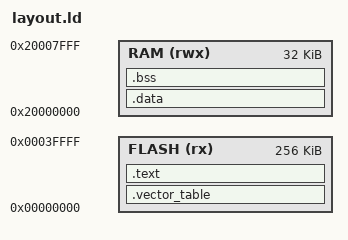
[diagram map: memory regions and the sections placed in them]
MEMORY
{
    FLASH (rx) : ORIGIN = 0x00000000, LENGTH = 256K
    RAM (rwx) : ORIGIN = 0x20000000, LENGTH = 32K
}

SECTIONS
{
    .vector_table ORIGIN(FLASH) :
    {
        LONG(ORIGIN(RAM) + LENGTH(RAM))
        KEEP(*(.reset))
        KEEP(*(.exceptions))
    } > FLASH

    .text :
    {
        *(.text*)
        *(.rodata*)
        _etext = .;
    } > FLASH

    .data : AT(ADDR(.text) + SIZEOF(.text))
    {
        _data = .;
        _ldata = LOADADDR (.data);
        *(vtable)
        *(.data*)
        _edata = .;
    } > RAM

    .bss :
    {
        _bss = .;
        *(.bss*)
        *(COMMON)
        _ebss = .;
    } > RAM

    /DISCARD/ :
    {
        *(.ARM.exidx*)
        *(.note.gnu.build-id*)
    }
}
